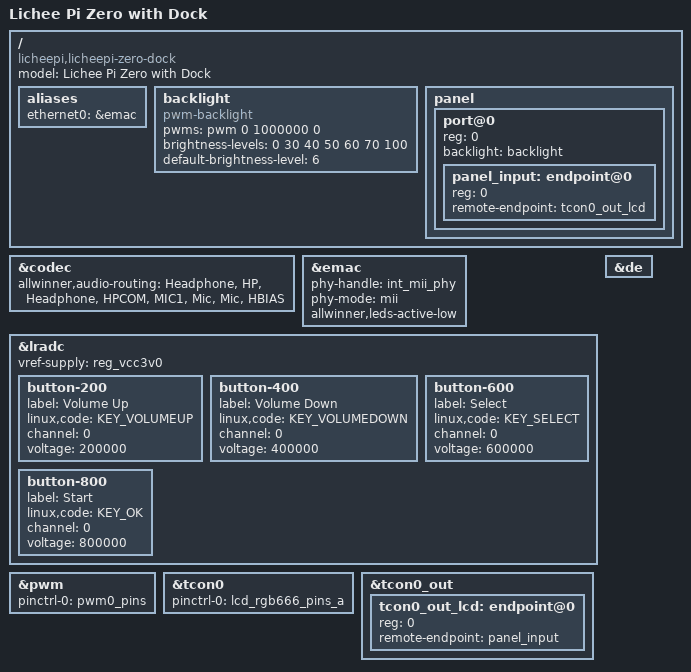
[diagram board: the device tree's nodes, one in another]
/*
 * Copyright (C) 2018 Icenowy Zheng <icenowy@aosc.io>
 *
 * SPDX-License-Identifier: (GPL-2.0+ OR X11)
 */

#include "sun8i-v3s-licheepi-zero.dts"
#include <dt-bindings/input/input.h>

 / {
        model = "Lichee Pi Zero with Dock";
        compatible = "licheepi,licheepi-zero-dock", "licheepi,licheepi-zero",
                     "allwinner,sun8i-v3s";
        aliases {
                ethernet0 = &emac;
        };

	backlight: backlight {
		compatible = "pwm-backlight";
		pwms = <&pwm 0 1000000 0>;
		brightness-levels = <0 30 40 50 60 70 100>;
		default-brightness-level = <6>;
	};

	panel: panel {
		#address-cells = <1>;
		#size-cells = <0>;

		port@0 {
			reg = <0>;
			backlight = <&backlight>;
			#address-cells = <1>;
			#size-cells = <0>;

			panel_input: endpoint@0 {
				reg = <0>;
				remote-endpoint = <&tcon0_out_lcd>;
			};
		};
	};
};

&codec {
        allwinner,audio-routing =
                "Headphone", "HP",
                "Headphone", "HPCOM",
                "MIC1", "Mic",
                "Mic",  "HBIAS";
        status = "okay";
};

&emac {
       phy-handle = <&int_mii_phy>;
       phy-mode = "mii";
       allwinner,leds-active-low;
       status = "okay";
};

&lradc {
        vref-supply = <&reg_vcc3v0>;
        status = "okay";

        button-200 {
                label = "Volume Up";
                linux,code = <KEY_VOLUMEUP>;
                channel = <0>;
                voltage = <200000>;
        };

        button-400 {
                label = "Volume Down";
                linux,code = <KEY_VOLUMEDOWN>;
                channel = <0>;
                voltage = <400000>;
        };

        button-600 {
                label = "Select";
                linux,code = <KEY_SELECT>;
                channel = <0>;
                voltage = <600000>;
        };

        button-800 {
                label = "Start";
                linux,code = <KEY_OK>;
                channel = <0>;
                voltage = <800000>;
        };
};

&de {
	status = "okay";
};

&pwm {
	pinctrl-names = "default";
	pinctrl-0 = <&pwm0_pins>;
	status = "okay";
};

&tcon0 {
	pinctrl-names = "default";
	pinctrl-0 = <&lcd_rgb666_pins_a>;
	status = "okay";
};

&tcon0_out {
	tcon0_out_lcd: endpoint@0 {
		reg = <0>;
		remote-endpoint = <&panel_input>;
	};
};
